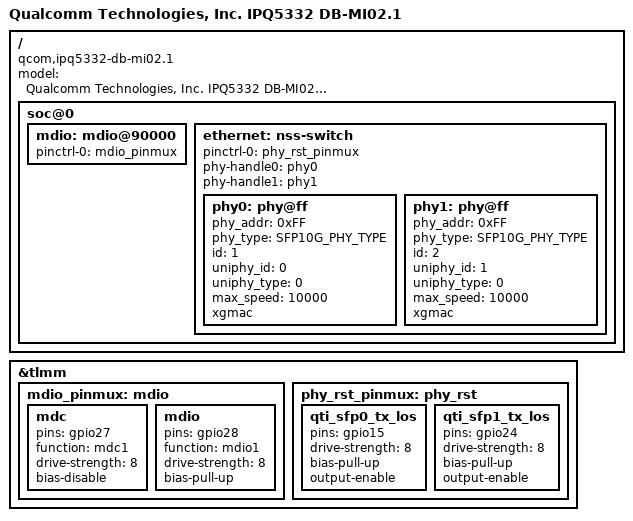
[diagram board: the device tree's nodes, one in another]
// SPDX-License-Identifier: GPL-2.0-only
/*
 * Copyright (c) Qualcomm Technologies, Inc. and/or its subsidiaries.
 */

/dts-v1/;

#include "ipq5332-rdp-common.dtsi"

/ {
	model = "Qualcomm Technologies, Inc. IPQ5332 DB-MI02.1";
	compatible = "qcom,ipq5332-db-mi02.1", "qcom,ipq5332";

	soc@0 {
		mdio: mdio@90000 {
			pinctrl-names = "default";
			pinctrl-0 = <&mdio_pinmux>;
			status = "okay";
		};

		ethernet: nss-switch {
			pinctrl-names = "default";
			pinctrl-0 = <&phy_rst_pinmux>;
			phy-handle0 = <&phy0>;
			phy-handle1 = <&phy1>;
			status = "okay";

			phy0: phy@ff {
				phy_addr = <0xFF>;
				phy_type = <SFP10G_PHY_TYPE>;
				id = <1>;
				uniphy_id = <0>;
				uniphy_type = <0>;
				max_speed = <10000>;
				xgmac;
			};

			phy1: phy@ff {
				phy_addr = <0xFF>;
				phy_type = <SFP10G_PHY_TYPE>;
				id = <2>;
				uniphy_id = <1>;
				uniphy_type = <0>;
				max_speed = <10000>;
				xgmac;
			};
		};
	};
};

&tlmm {
	mdio_pinmux: mdio {
		mdc {
			pins = "gpio27";
			function = "mdc1";
			drive-strength = <8>;
			bias-disable;
		};

		mdio {
			pins = "gpio28";
			function = "mdio1";
			drive-strength = <8>;
			bias-pull-up;
		};
	};

	phy_rst_pinmux: phy_rst {
		qti_sfp0_tx_los {
			pins = "gpio15";
			drive-strength = <8>;
			bias-pull-up;
			output-enable;
		};

		qti_sfp1_tx_los {
			pins = "gpio24";
			drive-strength = <8>;
			bias-pull-up;
			output-enable;
		};
	};
};
